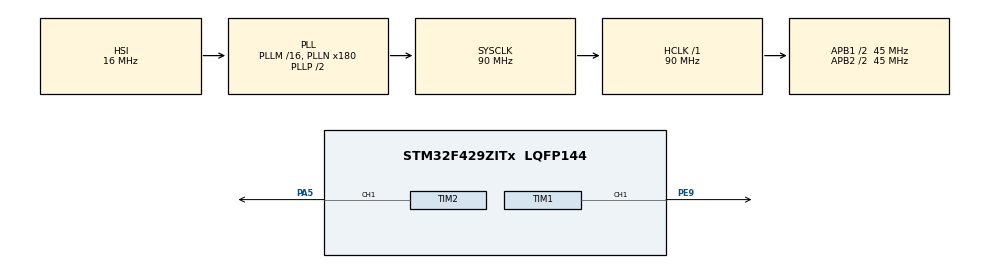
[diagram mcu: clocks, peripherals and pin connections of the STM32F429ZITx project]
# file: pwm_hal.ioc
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Mcu.Family=STM32F4
Mcu.Name=STM32F429ZITx
Mcu.Package=LQFP144
NVIC.PriorityGroup=NVIC_PRIORITYGROUP_4
PA5.Signal=S_TIM2_CH1_ETR
PE9.Signal=S_TIM1_CH1
ProjectManager.HeapSize=0x200
ProjectManager.StackSize=0x400
ProjectManager.TargetToolchain=MDK-ARM V5
RCC.48MHZClocksFreq_Value=45000000
RCC.AHBFreq_Value=90000000
RCC.APB1CLKDivider=RCC_HCLK_DIV2
RCC.APB1Freq_Value=45000000
RCC.APB1TimFreq_Value=90000000
RCC.APB2CLKDivider=RCC_HCLK_DIV2
RCC.APB2Freq_Value=45000000
RCC.APB2TimFreq_Value=90000000
RCC.CortexFreq_Value=90000000
RCC.HCLKFreq_Value=90000000
RCC.HSE_VALUE=25000000
RCC.HSI_VALUE=16000000
RCC.LSE_VALUE=32768
RCC.PLLN=180
RCC.SYSCLKFreq_VALUE=90000000
RCC.SYSCLKSource=RCC_SYSCLKSOURCE_PLLCLK
RCC.VCOOutputFreq_Value=180000000
SH.S_TIM1_CH1.0=TIM1_CH1,PWM Generation1 CH1
SH.S_TIM2_CH1_ETR.0=TIM2_CH1,PWM Generation1 CH1
TIM1.Channel-PWM\ Generation1\ CH1=TIM_CHANNEL_1
TIM1.Period=1000
TIM1.Prescaler=44999
TIM1.Pulse-PWM\ Generation1\ CH1=500
TIM2.Channel-PWM\ Generation1\ CH1=TIM_CHANNEL_1
TIM2.OCPolarity_1=TIM_OCPOLARITY_HIGH
TIM2.Period=1000
TIM2.Prescaler=44999
TIM2.Pulse-PWM\ Generation1\ CH1=500
VP_TIM1_VS_ClockSourceINT.Mode=Internal
VP_TIM2_VS_ClockSourceINT.Mode=Internal
board=custom

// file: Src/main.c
/* USER CODE BEGIN Header */
/**
  ******************************************************************************
  * @file           : main.c
  * @brief          : Main program body
  ******************************************************************************
  * @attention
  *
  * <h2><center>&copy; Copyright (c) 2020 STMicroelectronics.
  * All rights reserved.</center></h2>
  *
  * This software component is licensed by ST under BSD 3-Clause license,
  * the "License"; You may not use this file except in compliance with the
  * License. You may obtain a copy of the License at:
  *                        opensource.org/licenses/BSD-3-Clause
  *
  ******************************************************************************
  */
/* USER CODE END Header */

#include "main.h"

TIM_HandleTypeDef htim1;
TIM_HandleTypeDef htim2;

void SystemClock_Config(void);
static void MX_GPIO_Init(void);
static void MX_TIM1_Init(void);
static void MX_TIM2_Init(void);

int main(void)
{
  /* USER CODE BEGIN 1 */
uint16_t duty_cycle = 10;
  /* USER CODE END 1 */

  /* MCU Configuration--------------------------------------------------------*/

  /* Reset of all peripherals, Initializes the Flash interface and the Systick. */
  HAL_Init();

  /* Configure the system clock */
  SystemClock_Config();

  /* Initialize all configured peripherals */
  MX_GPIO_Init();
  MX_TIM1_Init();
  MX_TIM2_Init();
  /* USER CODE BEGIN 2 */
HAL_TIM_PWM_Start(&htim1, TIM_CHANNEL_1);
HAL_TIM_PWM_Start(&htim2, TIM_CHANNEL_1);
  /* USER CODE END 2 */

  /* Infinite loop */
  while (1)
  {

    /* USER CODE BEGIN 3 */
		/*
		htim1.Instance->CCR1 = duty_cycle;
		htim2.Instance->CCR1 = duty_cycle;
		duty_cycle +=10;
		if(duty_cycle > 90) duty_cycle = 10;
		HAL_Delay(1000);
		*/
  }
  /* USER CODE END 3 */
}

void SystemClock_Config(void)
{
  RCC_OscInitTypeDef RCC_OscInitStruct = {0};
  RCC_ClkInitTypeDef RCC_ClkInitStruct = {0};

  /** Configure the main internal regulator output voltage
  */
  __HAL_RCC_PWR_CLK_ENABLE();
  __HAL_PWR_VOLTAGESCALING_CONFIG(PWR_REGULATOR_VOLTAGE_SCALE3);
  /** Initializes the CPU, AHB and APB busses clocks
  */
  RCC_OscInitStruct.OscillatorType = RCC_OSCILLATORTYPE_HSI;
  RCC_OscInitStruct.HSIState = RCC_HSI_ON;
  RCC_OscInitStruct.HSICalibrationValue = RCC_HSICALIBRATION_DEFAULT;
  RCC_OscInitStruct.PLL.PLLState = RCC_PLL_ON;
  RCC_OscInitStruct.PLL.PLLSource = RCC_PLLSOURCE_HSI;
  RCC_OscInitStruct.PLL.PLLM = 16;
  RCC_OscInitStruct.PLL.PLLN = 180;
  RCC_OscInitStruct.PLL.PLLP = RCC_PLLP_DIV2;
  RCC_OscInitStruct.PLL.PLLQ = 4;
  if (HAL_RCC_OscConfig(&RCC_OscInitStruct) != HAL_OK)
  {
    Error_Handler();
  }
  /** Activate the Over-Drive mode
  */
  if (HAL_PWREx_EnableOverDrive() != HAL_OK)
  {
    Error_Handler();
  }
  /** Initializes the CPU, AHB and APB busses clocks
  */
  RCC_ClkInitStruct.ClockType = RCC_CLOCKTYPE_HCLK|RCC_CLOCKTYPE_SYSCLK
                              |RCC_CLOCKTYPE_PCLK1|RCC_CLOCKTYPE_PCLK2;
  RCC_ClkInitStruct.SYSCLKSource = RCC_SYSCLKSOURCE_PLLCLK;
  RCC_ClkInitStruct.AHBCLKDivider = RCC_SYSCLK_DIV1;
  RCC_ClkInitStruct.APB1CLKDivider = RCC_HCLK_DIV2;
  RCC_ClkInitStruct.APB2CLKDivider = RCC_HCLK_DIV2;

  if (HAL_RCC_ClockConfig(&RCC_ClkInitStruct, FLASH_LATENCY_2) != HAL_OK)
  {
    Error_Handler();
  }
}

static void MX_TIM1_Init(void)
{

  TIM_ClockConfigTypeDef sClockSourceConfig = {0};
  TIM_MasterConfigTypeDef sMasterConfig = {0};
  TIM_OC_InitTypeDef sConfigOC = {0};
  TIM_BreakDeadTimeConfigTypeDef sBreakDeadTimeConfig = {0};

  htim1.Instance = TIM1;
  htim1.Init.Prescaler = 44999;
  htim1.Init.CounterMode = TIM_COUNTERMODE_UP;
  htim1.Init.Period = 1000;
  htim1.Init.ClockDivision = TIM_CLOCKDIVISION_DIV1;
  htim1.Init.RepetitionCounter = 0;
  htim1.Init.AutoReloadPreload = TIM_AUTORELOAD_PRELOAD_DISABLE;
  if (HAL_TIM_Base_Init(&htim1) != HAL_OK)
  {
    Error_Handler();
  }
  sClockSourceConfig.ClockSource = TIM_CLOCKSOURCE_INTERNAL;
  if (HAL_TIM_ConfigClockSource(&htim1, &sClockSourceConfig) != HAL_OK)
  {
    Error_Handler();
  }
  if (HAL_TIM_PWM_Init(&htim1) != HAL_OK)
  {
    Error_Handler();
  }
  sMasterConfig.MasterOutputTrigger = TIM_TRGO_RESET;
  sMasterConfig.MasterSlaveMode = TIM_MASTERSLAVEMODE_DISABLE;
  if (HAL_TIMEx_MasterConfigSynchronization(&htim1, &sMasterConfig) != HAL_OK)
  {
    Error_Handler();
  }
  sConfigOC.OCMode = TIM_OCMODE_PWM1;
  sConfigOC.Pulse = 500;
  sConfigOC.OCPolarity = TIM_OCPOLARITY_HIGH;
  sConfigOC.OCNPolarity = TIM_OCNPOLARITY_HIGH;
  sConfigOC.OCFastMode = TIM_OCFAST_DISABLE;
  sConfigOC.OCIdleState = TIM_OCIDLESTATE_RESET;
  sConfigOC.OCNIdleState = TIM_OCNIDLESTATE_RESET;
  if (HAL_TIM_PWM_ConfigChannel(&htim1, &sConfigOC, TIM_CHANNEL_1) != HAL_OK)
  {
    Error_Handler();
  }
  sBreakDeadTimeConfig.OffStateRunMode = TIM_OSSR_DISABLE;
  sBreakDeadTimeConfig.OffStateIDLEMode = TIM_OSSI_DISABLE;
  sBreakDeadTimeConfig.LockLevel = TIM_LOCKLEVEL_OFF;
  sBreakDeadTimeConfig.DeadTime = 0;
  sBreakDeadTimeConfig.BreakState = TIM_BREAK_DISABLE;
  sBreakDeadTimeConfig.BreakPolarity = TIM_BREAKPOLARITY_HIGH;
  sBreakDeadTimeConfig.AutomaticOutput = TIM_AUTOMATICOUTPUT_DISABLE;
  if (HAL_TIMEx_ConfigBreakDeadTime(&htim1, &sBreakDeadTimeConfig) != HAL_OK)
  {
    Error_Handler();
  }
  HAL_TIM_MspPostInit(&htim1);

}

static void MX_TIM2_Init(void)
{

  TIM_ClockConfigTypeDef sClockSourceConfig = {0};
  TIM_MasterConfigTypeDef sMasterConfig = {0};
  TIM_OC_InitTypeDef sConfigOC = {0};

  htim2.Instance = TIM2;
  htim2.Init.Prescaler = 44999;
  htim2.Init.CounterMode = TIM_COUNTERMODE_UP;
  htim2.Init.Period = 1000;
  htim2.Init.ClockDivision = TIM_CLOCKDIVISION_DIV1;
  htim2.Init.AutoReloadPreload = TIM_AUTORELOAD_PRELOAD_DISABLE;
  if (HAL_TIM_Base_Init(&htim2) != HAL_OK)
  {
    Error_Handler();
  }
  sClockSourceConfig.ClockSource = TIM_CLOCKSOURCE_INTERNAL;
  if (HAL_TIM_ConfigClockSource(&htim2, &sClockSourceConfig) != HAL_OK)
  {
    Error_Handler();
  }
  if (HAL_TIM_PWM_Init(&htim2) != HAL_OK)
  {
    Error_Handler();
  }
  sMasterConfig.MasterOutputTrigger = TIM_TRGO_RESET;
  sMasterConfig.MasterSlaveMode = TIM_MASTERSLAVEMODE_DISABLE;
  if (HAL_TIMEx_MasterConfigSynchronization(&htim2, &sMasterConfig) != HAL_OK)
  {
    Error_Handler();
  }
  sConfigOC.OCMode = TIM_OCMODE_PWM1;
  sConfigOC.Pulse = 500;
  sConfigOC.OCPolarity = TIM_OCPOLARITY_HIGH;
  sConfigOC.OCFastMode = TIM_OCFAST_DISABLE;
  if (HAL_TIM_PWM_ConfigChannel(&htim2, &sConfigOC, TIM_CHANNEL_1) != HAL_OK)
  {
    Error_Handler();
  }
  HAL_TIM_MspPostInit(&htim2);

}

static void MX_GPIO_Init(void)
{

  /* GPIO Ports Clock Enable */
  __HAL_RCC_GPIOA_CLK_ENABLE();
  __HAL_RCC_GPIOE_CLK_ENABLE();

}

void Error_Handler(void)
{
}

/************************ (C) COPYRIGHT STMicroelectronics *****END OF FILE****/
